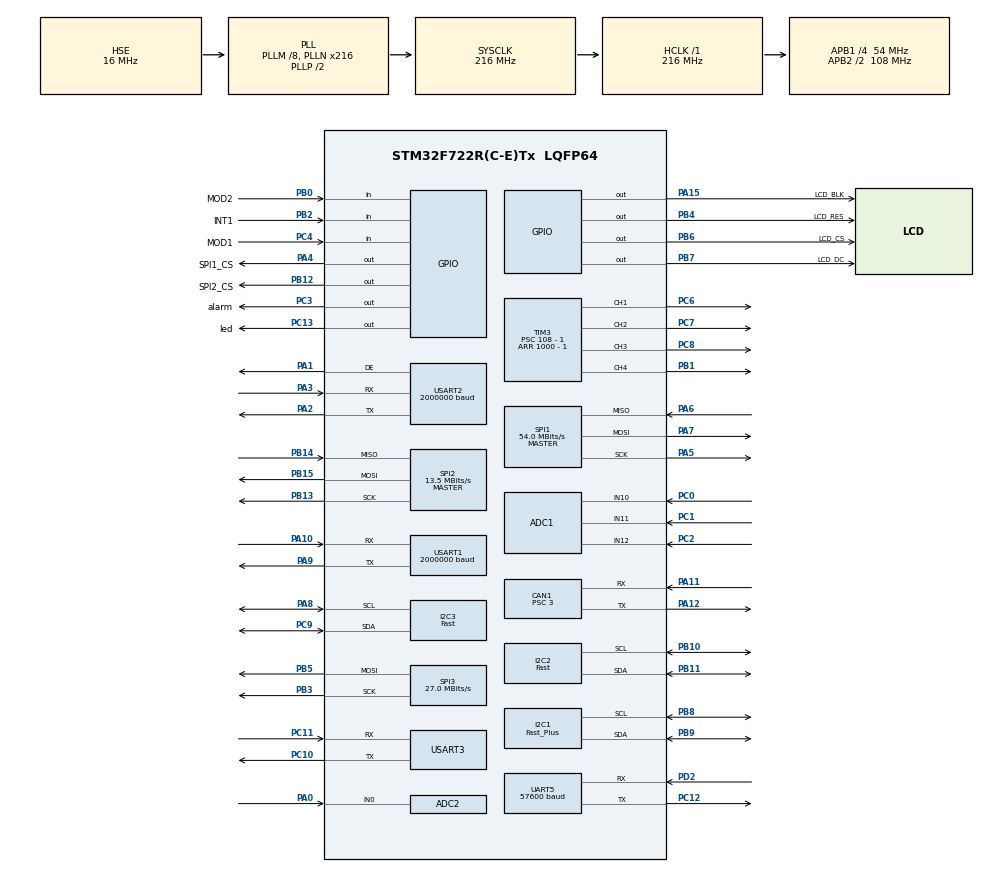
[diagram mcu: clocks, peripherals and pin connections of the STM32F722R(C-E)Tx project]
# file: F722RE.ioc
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ADC1.Channel-0\#ChannelRegularConversion=ADC_CHANNEL_10
ADC1.Channel-1\#ChannelRegularConversion=ADC_CHANNEL_11
ADC1.Channel-2\#ChannelRegularConversion=ADC_CHANNEL_12
ADC1.ClockPrescaler=ADC_CLOCK_SYNC_PCLK_DIV8
ADC1.ContinuousConvMode=ENABLE
ADC1.DMAContinuousRequests=ENABLE
ADC1.EOCSelection=ADC_EOC_SEQ_CONV
ADC1.NbrOfConversion=3
ADC1.NbrOfConversionFlag=1
ADC1.Rank-0\#ChannelRegularConversion=1
ADC1.Rank-1\#ChannelRegularConversion=2
ADC1.Rank-2\#ChannelRegularConversion=3
ADC1.SamplingTime-0\#ChannelRegularConversion=ADC_SAMPLETIME_480CYCLES
ADC1.SamplingTime-1\#ChannelRegularConversion=ADC_SAMPLETIME_480CYCLES
ADC1.SamplingTime-2\#ChannelRegularConversion=ADC_SAMPLETIME_480CYCLES
ADC1.ScanConvMode=ADC_SCAN_ENABLE
ADC1.master=1
ADC2.Channel-0\#ChannelRegularConversion=ADC_CHANNEL_0
ADC2.ClockPrescaler=ADC_CLOCK_SYNC_PCLK_DIV8
ADC2.ContinuousConvMode=ENABLE
ADC2.DMAContinuousRequests=ENABLE
ADC2.ExternalTrigConv=ADC_SOFTWARE_START
ADC2.ExternalTrigConvEdge=ADC_EXTERNALTRIGCONVEDGE_NONE
ADC2.NbrOfConversionFlag=1
ADC2.Rank-0\#ChannelRegularConversion=1
ADC2.SamplingTime-0\#ChannelRegularConversion=ADC_SAMPLETIME_480CYCLES
CAN1.BS1=CAN_BS1_13TQ
CAN1.BS2=CAN_BS2_4TQ
CAN1.CalculateBaudRate=1000000
CAN1.CalculateTimeBit=1000
CAN1.CalculateTimeQuantum=55.55555555555556
CAN1.Prescaler=3
CAN1.SJW=CAN_SJW_3TQ
CORTEX_M7.MPU_Control=__NULL
CORTEX_M7.default_mode_Activation=1
Dma.ADC1.4.Direction=DMA_PERIPH_TO_MEMORY
Dma.ADC1.4.FIFOMode=DMA_FIFOMODE_DISABLE
Dma.ADC1.4.Instance=DMA2_Stream0
Dma.ADC1.4.MemDataAlignment=DMA_MDATAALIGN_HALFWORD
Dma.ADC1.4.MemInc=DMA_MINC_ENABLE
Dma.ADC1.4.Mode=DMA_CIRCULAR
Dma.ADC1.4.PeriphDataAlignment=DMA_PDATAALIGN_HALFWORD
Dma.ADC1.4.PeriphInc=DMA_PINC_DISABLE
Dma.ADC1.4.Priority=DMA_PRIORITY_LOW
Dma.ADC2.5.Direction=DMA_PERIPH_TO_MEMORY
Dma.ADC2.5.FIFOMode=DMA_FIFOMODE_DISABLE
Dma.ADC2.5.Instance=DMA2_Stream3
Dma.ADC2.5.MemDataAlignment=DMA_MDATAALIGN_HALFWORD
Dma.ADC2.5.MemInc=DMA_MINC_ENABLE
Dma.ADC2.5.Mode=DMA_CIRCULAR
Dma.ADC2.5.PeriphDataAlignment=DMA_PDATAALIGN_HALFWORD
Dma.ADC2.5.PeriphInc=DMA_PINC_DISABLE
Dma.ADC2.5.Priority=DMA_PRIORITY_LOW
Dma.Request0=USART1_RX
Dma.Request1=USART1_TX
Dma.Request2=USART2_RX
Dma.Request3=USART3_RX
Dma.Request4=ADC1
Dma.Request5=ADC2
Dma.Request6=UART5_RX
Dma.UART5_RX.6.Direction=DMA_PERIPH_TO_MEMORY
Dma.UART5_RX.6.FIFOMode=DMA_FIFOMODE_DISABLE
Dma.UART5_RX.6.Instance=DMA1_Stream0
Dma.UART5_RX.6.MemDataAlignment=DMA_MDATAALIGN_BYTE
Dma.UART5_RX.6.MemInc=DMA_MINC_ENABLE
Dma.UART5_RX.6.Mode=DMA_NORMAL
Dma.UART5_RX.6.PeriphDataAlignment=DMA_PDATAALIGN_BYTE
Dma.UART5_RX.6.PeriphInc=DMA_PINC_DISABLE
Dma.UART5_RX.6.Priority=DMA_PRIORITY_LOW
Dma.USART1_RX.0.Direction=DMA_PERIPH_TO_MEMORY
Dma.USART1_RX.0.FIFOMode=DMA_FIFOMODE_DISABLE
Dma.USART1_RX.0.Instance=DMA2_Stream2
Dma.USART1_RX.0.MemDataAlignment=DMA_MDATAALIGN_BYTE
Dma.USART1_RX.0.MemInc=DMA_MINC_ENABLE
Dma.USART1_RX.0.Mode=DMA_NORMAL
Dma.USART1_RX.0.PeriphDataAlignment=DMA_PDATAALIGN_BYTE
Dma.USART1_RX.0.PeriphInc=DMA_PINC_DISABLE
Dma.USART1_RX.0.Priority=DMA_PRIORITY_LOW
Dma.USART1_TX.1.Direction=DMA_MEMORY_TO_PERIPH
Dma.USART1_TX.1.FIFOMode=DMA_FIFOMODE_DISABLE
Dma.USART1_TX.1.Instance=DMA2_Stream7
Dma.USART1_TX.1.MemDataAlignment=DMA_MDATAALIGN_BYTE
Dma.USART1_TX.1.MemInc=DMA_MINC_ENABLE
Dma.USART1_TX.1.Mode=DMA_NORMAL
Dma.USART1_TX.1.PeriphDataAlignment=DMA_PDATAALIGN_BYTE
Dma.USART1_TX.1.PeriphInc=DMA_PINC_DISABLE
Dma.USART1_TX.1.Priority=DMA_PRIORITY_LOW
Dma.USART2_RX.2.Direction=DMA_PERIPH_TO_MEMORY
Dma.USART2_RX.2.FIFOMode=DMA_FIFOMODE_DISABLE
Dma.USART2_RX.2.Instance=DMA1_Stream5
Dma.USART2_RX.2.MemDataAlignment=DMA_MDATAALIGN_BYTE
Dma.USART2_RX.2.MemInc=DMA_MINC_ENABLE
Dma.USART2_RX.2.Mode=DMA_NORMAL
Dma.USART2_RX.2.PeriphDataAlignment=DMA_PDATAALIGN_BYTE
Dma.USART2_RX.2.PeriphInc=DMA_PINC_DISABLE
Dma.USART2_RX.2.Priority=DMA_PRIORITY_LOW
Dma.USART3_RX.3.Direction=DMA_PERIPH_TO_MEMORY
Dma.USART3_RX.3.FIFOMode=DMA_FIFOMODE_DISABLE
Dma.USART3_RX.3.Instance=DMA1_Stream1
Dma.USART3_RX.3.MemDataAlignment=DMA_MDATAALIGN_BYTE
Dma.USART3_RX.3.MemInc=DMA_MINC_ENABLE
Dma.USART3_RX.3.Mode=DMA_NORMAL
Dma.USART3_RX.3.PeriphDataAlignment=DMA_PDATAALIGN_BYTE
Dma.USART3_RX.3.PeriphInc=DMA_PINC_DISABLE
Dma.USART3_RX.3.Priority=DMA_PRIORITY_LOW
FREERTOS.Tasks01=defaultTask,8,128,StartDefaultTask,Default,NULL,Dynamic,NULL,NULL;sys,8,256,app_sys,As external,NULL,Dynamic,NULL,NULL;lcdshow,8,512,app_lcdshow,As external,NULL,Dynamic,NULL,NULL;sensor,16,256,app_sensor,As external,NULL,Dynamic,NULL,NULL;gps,16,256,app_gps,As external,NULL,Dynamic,NULL,NULL;comm,8,512,app_comm,As external,NULL,Dynamic,NULL,NULL
FREERTOS.configMINIMAL_STACK_SIZE=128
FREERTOS.configTOTAL_HEAP_SIZE=32768
FREERTOS.configUSE_NEWLIB_REENTRANT=1
I2C1.I2C_Speed_Mode=I2C_Fast_Plus
I2C1.Speed=1000
I2C1.Timing=0x00200922
I2C2.I2C_Speed_Mode=I2C_Fast
I2C2.Timing=0x6000030D
I2C3.I2C_Speed_Mode=I2C_Fast
I2C3.Timing=0x6000030D
Mcu.Family=STM32F7
Mcu.Name=STM32F722R(C-E)Tx
Mcu.Package=LQFP64
NVIC.CAN1_RX0_IRQn=true\:5\:0\:false\:false\:true\:true\:true\:true\:true
NVIC.CAN1_RX1_IRQn=true\:5\:0\:false\:false\:true\:true\:true\:true\:true
NVIC.DMA1_Stream0_IRQn=true\:5\:0\:false\:false\:true\:true\:false\:true\:true
NVIC.DMA1_Stream1_IRQn=true\:5\:0\:false\:false\:true\:true\:false\:true\:true
NVIC.DMA1_Stream5_IRQn=true\:5\:0\:false\:false\:true\:true\:false\:true\:true
NVIC.DMA2_Stream0_IRQn=true\:5\:0\:false\:false\:true\:true\:false\:true\:true
NVIC.DMA2_Stream2_IRQn=true\:5\:0\:false\:false\:true\:true\:false\:true\:true
NVIC.DMA2_Stream3_IRQn=true\:5\:0\:false\:false\:true\:true\:false\:true\:true
NVIC.DMA2_Stream7_IRQn=true\:5\:0\:false\:false\:true\:true\:false\:true\:true
NVIC.PriorityGroup=NVIC_PRIORITYGROUP_4
NVIC.TIM6_DAC_IRQn=true\:15\:0\:false\:false\:true\:false\:false\:true\:true
NVIC.TIM8_TRG_COM_TIM14_IRQn=true\:5\:0\:false\:false\:true\:true\:true\:true\:true
NVIC.TimeBase=TIM6_DAC_IRQn
NVIC.TimeBaseIP=TIM6
NVIC.UART5_IRQn=true\:5\:0\:false\:false\:true\:true\:true\:true\:true
NVIC.USART1_IRQn=true\:5\:0\:false\:false\:true\:true\:true\:true\:true
NVIC.USART2_IRQn=true\:5\:0\:false\:false\:true\:true\:true\:true\:true
NVIC.USART3_IRQn=true\:5\:0\:false\:false\:true\:true\:true\:true\:true
PA0-WKUP.Signal=ADCx_IN0
PA1.Mode=Hardware Flow Control (RS485)
PA1.Signal=USART2_DE
PA10.Mode=Asynchronous
PA10.Signal=USART1_RX
PA11.Mode=CAN_Activate
PA11.Signal=CAN1_RX
PA12.Mode=CAN_Activate
PA12.Signal=CAN1_TX
PA13.Mode=Serial_Wire
PA13.Signal=SYS_JTMS-SWDIO
PA14.Mode=Serial_Wire
PA14.Signal=SYS_JTCK-SWCLK
PA15.GPIO_Label=LCD_BLK
PA15.Signal=GPIO_Output
PA2.Mode=Asynchronous
PA2.Signal=USART2_TX
PA3.Mode=Asynchronous
PA3.Signal=USART2_RX
PA4.GPIO_Label=SPI1_CS
PA4.Signal=GPIO_Output
PA5.Mode=Full_Duplex_Master
PA5.Signal=SPI1_SCK
PA6.Mode=Full_Duplex_Master
PA6.Signal=SPI1_MISO
PA7.Mode=Full_Duplex_Master
PA7.Signal=SPI1_MOSI
PA8.Mode=I2C
PA8.Signal=I2C3_SCL
PA9.Mode=Asynchronous
PA9.Signal=USART1_TX
PB0.GPIO_Label=MOD2
PB0.GPIO_PuPd=GPIO_PULLUP
PB0.Signal=GPIO_Input
PB1.Signal=S_TIM3_CH4
PB10.Mode=I2C
PB10.Signal=I2C2_SCL
PB11.Mode=I2C
PB11.Signal=I2C2_SDA
PB12.GPIO_Label=SPI2_CS
PB12.Signal=GPIO_Output
PB13.Mode=Full_Duplex_Master
PB13.Signal=SPI2_SCK
PB14.Mode=Full_Duplex_Master
PB14.Signal=SPI2_MISO
PB15.Mode=Full_Duplex_Master
PB15.Signal=SPI2_MOSI
PB2.GPIO_Label=INT1
PB2.Signal=GPIO_Input
PB3.Mode=TX_Only_Simplex_Unidirect_Master
PB3.Signal=SPI3_SCK
PB4.GPIO_Label=LCD_RES
PB4.Signal=GPIO_Output
PB5.Mode=TX_Only_Simplex_Unidirect_Master
PB5.Signal=SPI3_MOSI
PB6.GPIO_Label=LCD_CS
PB6.Signal=GPIO_Output
PB7.GPIO_Label=LCD_DC
PB7.Signal=GPIO_Output
PB8.Mode=I2C
PB8.Signal=I2C1_SCL
PB9.Mode=I2C
PB9.Signal=I2C1_SDA
PC0.Signal=ADCx_IN10
PC1.Signal=ADCx_IN11
PC10.Mode=Asynchronous
PC10.Signal=USART3_TX
PC11.Mode=Asynchronous
PC11.Signal=USART3_RX
PC12.Mode=Asynchronous
PC12.Signal=UART5_TX
PC13.GPIO_Label=led
PC13.Signal=GPIO_Output
PC14-OSC32_IN.Mode=LSE-External-Oscillator
PC14-OSC32_IN.Signal=RCC_OSC32_IN
PC15-OSC32_OUT.Mode=LSE-External-Oscillator
PC15-OSC32_OUT.Signal=RCC_OSC32_OUT
PC2.Signal=ADCx_IN12
PC3.GPIO_Label=alarm
PC3.Signal=GPIO_Output
PC4.GPIO_Label=MOD1
PC4.GPIO_PuPd=GPIO_PULLUP
PC4.Signal=GPIO_Input
PC6.Signal=S_TIM3_CH1
PC7.Signal=S_TIM3_CH2
PC8.Signal=S_TIM3_CH3
PC9.Mode=I2C
PC9.Signal=I2C3_SDA
PD2.Mode=Asynchronous
PD2.Signal=UART5_RX
PH0-OSC_IN.Mode=HSE-External-Oscillator
PH0-OSC_IN.Signal=RCC_OSC_IN
PH1-OSC_OUT.Mode=HSE-External-Oscillator
PH1-OSC_OUT.Signal=RCC_OSC_OUT
ProjectManager.HeapSize=0x1000
ProjectManager.StackSize=0x2000
ProjectManager.TargetToolchain=STM32CubeIDE
RCC.AHBFreq_Value=216000000
RCC.APB1CLKDivider=RCC_HCLK_DIV4
RCC.APB1Freq_Value=54000000
RCC.APB1TimFreq_Value=108000000
RCC.APB2CLKDivider=RCC_HCLK_DIV2
RCC.APB2Freq_Value=108000000
RCC.APB2TimFreq_Value=216000000
RCC.CortexFreq_Value=216000000
RCC.HCLKFreq_Value=216000000
RCC.HSE_VALUE=16000000
RCC.HSI_VALUE=16000000
RCC.PLLM=8
RCC.PLLN=216
RCC.PLLSourceVirtual=RCC_PLLSOURCE_HSE
RCC.SYSCLKFreq_VALUE=216000000
RCC.SYSCLKSource=RCC_SYSCLKSOURCE_PLLCLK
RCC.USBFreq_Value=216000000
RCC.VCOOutputFreq_Value=432000000
SH.ADCx_IN0.0=ADC2_IN0,IN0
SH.ADCx_IN10.0=ADC1_IN10,IN10
SH.ADCx_IN11.0=ADC1_IN11,IN11
SH.ADCx_IN12.0=ADC1_IN12,IN12
SH.S_TIM3_CH1.0=TIM3_CH1,PWM Generation1 CH1
SH.S_TIM3_CH2.0=TIM3_CH2,PWM Generation2 CH2
SH.S_TIM3_CH3.0=TIM3_CH3,PWM Generation3 CH3
SH.S_TIM3_CH4.0=TIM3_CH4,PWM Generation4 CH4
SPI1.BaudRatePrescaler=SPI_BAUDRATEPRESCALER_2
SPI1.CLKPhase=SPI_PHASE_1EDGE
SPI1.CalculateBaudRate=54.0 MBits/s
SPI1.DataSize=SPI_DATASIZE_8BIT
SPI1.Direction=SPI_DIRECTION_2LINES
SPI1.Mode=SPI_MODE_MASTER
SPI1.VirtualType=VM_MASTER
SPI2.BaudRatePrescaler=SPI_BAUDRATEPRESCALER_4
SPI2.CLKPhase=SPI_PHASE_1EDGE
SPI2.CalculateBaudRate=13.5 MBits/s
SPI2.DataSize=SPI_DATASIZE_8BIT
SPI2.Direction=SPI_DIRECTION_2LINES
SPI2.Mode=SPI_MODE_MASTER
SPI2.VirtualType=VM_MASTER
SPI3.BaudRatePrescaler=SPI_BAUDRATEPRESCALER_2
SPI3.CalculateBaudRate=27.0 MBits/s
SPI3.DataSize=SPI_DATASIZE_8BIT
SPI3.Direction=SPI_DIRECTION_2LINES
SPI3.Mode=SPI_MODE_MASTER
SPI3.VirtualType=VM_MASTER
TIM14.AutoReloadPreload=TIM_AUTORELOAD_PRELOAD_ENABLE
TIM14.Period=5000 - 1
TIM14.Prescaler=108 - 1
TIM3.Channel-PWM\ Generation1\ CH1=TIM_CHANNEL_1
TIM3.Channel-PWM\ Generation2\ CH2=TIM_CHANNEL_2
TIM3.Channel-PWM\ Generation3\ CH3=TIM_CHANNEL_3
TIM3.Channel-PWM\ Generation4\ CH4=TIM_CHANNEL_4
TIM3.Period=1000 - 1
TIM3.Prescaler=108 - 1
TIM7.Prescaler=108 - 1
UART5.BaudRate=57600
USART1.BaudRate=2000000
USART1.VirtualMode-Asynchronous=VM_ASYNC
USART2.BaudRate=2000000
USART2.VirtualMode-Asynchronous=VM_ASYNC
USART2.VirtualMode-Hardware\ Flow\ Control\ (RS485)=VM_ASYNC
USART3.VirtualMode-Asynchronous=VM_ASYNC
VP_FREERTOS_VS_CMSIS_V2.Mode=CMSIS_V2
VP_SYS_VS_tim6.Mode=TIM6
VP_TIM14_VS_ClockSourceINT.Mode=Enable_Timer
VP_TIM3_VS_ClockSourceINT.Mode=Internal
VP_TIM7_VS_ClockSourceINT.Mode=Enable_Timer
board=custom

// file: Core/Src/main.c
/* USER CODE BEGIN Header */
/**
  ******************************************************************************
  * @file           : main.c
  * @brief          : Main program body
  ******************************************************************************
  * @attention
  *
  * Copyright (c) 2026 STMicroelectronics.
  * All rights reserved.
  *
  * This software is licensed under terms that can be found in the LICENSE file
  * in the root directory of this software component.
  * If no LICENSE file comes with this software, it is provided AS-IS.
  *
  ******************************************************************************
  */
/* USER CODE END Header */
#include "main.h"
#include "cmsis_os.h"
#include "adc.h"
#include "can.h"
#include "dma.h"
#include "i2c.h"
#include "spi.h"
#include "tim.h"
#include "usart.h"
#include "gpio.h"

/* USER CODE BEGIN Includes */
extern void app_imu_timer_callback(void);
extern void sys_main_init(void);
/* USER CODE END Includes */

void SystemClock_Config(void);
void MX_FREERTOS_Init(void);

int main(void)
{

  /* MCU Configuration--------------------------------------------------------*/

  /* Reset of all peripherals, Initializes the Flash interface and the Systick. */
  HAL_Init();

  /* USER CODE BEGIN Init */
  HAL_RCC_DeInit();
  /* USER CODE END Init */

  /* Configure the system clock */
  SystemClock_Config();

  /* Initialize all configured peripherals */
  MX_GPIO_Init();
  MX_DMA_Init();
  MX_CAN1_Init();
  MX_I2C1_Init();
  MX_I2C2_Init();
  MX_I2C3_Init();
  MX_SPI1_Init();
  MX_SPI2_Init();
  MX_SPI3_Init();
  MX_USART1_UART_Init();
  MX_USART2_UART_Init();
  MX_USART3_UART_Init();
  MX_TIM7_Init();
  MX_TIM14_Init();
  MX_ADC1_Init();
  MX_ADC2_Init();
  MX_TIM3_Init();
  MX_UART5_Init();
  /* USER CODE BEGIN 2 */
  sys_main_init();
  /* USER CODE END 2 */

  /* Init scheduler */
  osKernelInitialize();  /* Call init function for freertos objects (in cmsis_os2.c) */
  MX_FREERTOS_Init();

  /* Start scheduler */
  osKernelStart();

  /* We should never get here as control is now taken by the scheduler */

  /* Infinite loop */
  while (1)
  {

  }
}

void SystemClock_Config(void)
{
  RCC_OscInitTypeDef RCC_OscInitStruct = {0};
  RCC_ClkInitTypeDef RCC_ClkInitStruct = {0};

  /** Configure LSE Drive Capability
  */
  HAL_PWR_EnableBkUpAccess();

  /** Configure the main internal regulator output voltage
  */
  __HAL_RCC_PWR_CLK_ENABLE();
  __HAL_PWR_VOLTAGESCALING_CONFIG(PWR_REGULATOR_VOLTAGE_SCALE1);

  /** Initializes the RCC Oscillators according to the specified parameters
  * in the RCC_OscInitTypeDef structure.
  */
  RCC_OscInitStruct.OscillatorType = RCC_OSCILLATORTYPE_HSE;
  RCC_OscInitStruct.HSEState = RCC_HSE_ON;
  RCC_OscInitStruct.PLL.PLLState = RCC_PLL_ON;
  RCC_OscInitStruct.PLL.PLLSource = RCC_PLLSOURCE_HSE;
  RCC_OscInitStruct.PLL.PLLM = 8;
  RCC_OscInitStruct.PLL.PLLN = 216;
  RCC_OscInitStruct.PLL.PLLP = RCC_PLLP_DIV2;
  RCC_OscInitStruct.PLL.PLLQ = 2;
  if (HAL_RCC_OscConfig(&RCC_OscInitStruct) != HAL_OK)
  {
    Error_Handler();
  }

  /** Activate the Over-Drive mode
  */
  if (HAL_PWREx_EnableOverDrive() != HAL_OK)
  {
    Error_Handler();
  }

  /** Initializes the CPU, AHB and APB buses clocks
  */
  RCC_ClkInitStruct.ClockType = RCC_CLOCKTYPE_HCLK|RCC_CLOCKTYPE_SYSCLK
                              |RCC_CLOCKTYPE_PCLK1|RCC_CLOCKTYPE_PCLK2;
  RCC_ClkInitStruct.SYSCLKSource = RCC_SYSCLKSOURCE_PLLCLK;
  RCC_ClkInitStruct.AHBCLKDivider = RCC_SYSCLK_DIV1;
  RCC_ClkInitStruct.APB1CLKDivider = RCC_HCLK_DIV4;
  RCC_ClkInitStruct.APB2CLKDivider = RCC_HCLK_DIV2;

  if (HAL_RCC_ClockConfig(&RCC_ClkInitStruct, FLASH_LATENCY_7) != HAL_OK)
  {
    Error_Handler();
  }
}

void HAL_TIM_PeriodElapsedCallback(TIM_HandleTypeDef *htim)
{
  if (htim->Instance == TIM6)
  {
    HAL_IncTick();
  }
  /* USER CODE BEGIN Callback 1 */
  if (htim->Instance == TIM14)
  {
    app_imu_timer_callback();
  }
  /* USER CODE END Callback 1 */
}

void Error_Handler(void)
{
  __disable_irq();
  while (1)
  {
  }
}

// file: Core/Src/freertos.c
/* USER CODE BEGIN Header */
/**
  ******************************************************************************
  * File Name          : freertos.c
  * Description        : Code for freertos applications
  ******************************************************************************
  * @attention
  *
  * Copyright (c) 2026 STMicroelectronics.
  * All rights reserved.
  *
  * This software is licensed under terms that can be found in the LICENSE file
  * in the root directory of this software component.
  * If no LICENSE file comes with this software, it is provided AS-IS.
  *
  ******************************************************************************
  */
/* USER CODE END Header */

#include "FreeRTOS.h"
#include "task.h"
#include "main.h"
#include "cmsis_os.h"

/* Definitions for defaultTask */
osThreadId_t defaultTaskHandle;
const osThreadAttr_t defaultTask_attributes = {
  .name = "defaultTask",
  .stack_size = 128 * 4,
  .priority = (osPriority_t) osPriorityLow,
};
/* Definitions for sys */
osThreadId_t sysHandle;
const osThreadAttr_t sys_attributes = {
  .name = "sys",
  .stack_size = 256 * 4,
  .priority = (osPriority_t) osPriorityLow,
};
/* Definitions for lcdshow */
osThreadId_t lcdshowHandle;
const osThreadAttr_t lcdshow_attributes = {
  .name = "lcdshow",
  .stack_size = 512 * 4,
  .priority = (osPriority_t) osPriorityLow,
};
/* Definitions for sensor */
osThreadId_t sensorHandle;
const osThreadAttr_t sensor_attributes = {
  .name = "sensor",
  .stack_size = 256 * 4,
  .priority = (osPriority_t) osPriorityBelowNormal,
};
/* Definitions for gps */
osThreadId_t gpsHandle;
const osThreadAttr_t gps_attributes = {
  .name = "gps",
  .stack_size = 256 * 4,
  .priority = (osPriority_t) osPriorityBelowNormal,
};
/* Definitions for comm */
osThreadId_t commHandle;
const osThreadAttr_t comm_attributes = {
  .name = "comm",
  .stack_size = 512 * 4,
  .priority = (osPriority_t) osPriorityLow,
};

void StartDefaultTask(void *argument);
extern void app_sys(void *argument);
extern void app_lcdshow(void *argument);
extern void app_sensor(void *argument);
extern void app_gps(void *argument);
extern void app_comm(void *argument);

void MX_FREERTOS_Init(void); /* (MISRA C 2004 rule 8.1) */

void MX_FREERTOS_Init(void) {

  /* Create the thread(s) */
  /* creation of defaultTask */
  defaultTaskHandle = osThreadNew(StartDefaultTask, NULL, &defaultTask_attributes);

  /* creation of sys */
  sysHandle = osThreadNew(app_sys, NULL, &sys_attributes);

  /* creation of lcdshow */
  lcdshowHandle = osThreadNew(app_lcdshow, NULL, &lcdshow_attributes);

  /* creation of sensor */
  sensorHandle = osThreadNew(app_sensor, NULL, &sensor_attributes);

  /* creation of gps */
  gpsHandle = osThreadNew(app_gps, NULL, &gps_attributes);

  /* creation of comm */
  commHandle = osThreadNew(app_comm, NULL, &comm_attributes);

}

void StartDefaultTask(void *argument)
{
  for(;;)
  {
    osDelay(1);
  }
}
